# nrf54h20_enga_application register map
Vendor: Nordic Semiconductor; Series: nRF54h; File version: 1
CPU: CM33 r0p4, little endian, MPU, FPU, 3 interrupt priority bits, 480 interrupts, 4 SAU regions
Registers are 32-bit, read-write, reset 0x0 unless marked. A register's access mark holds for its fields unless they carry their own. Offsets are from the block's base; [hi:lo] are bit positions; lines under a group give offsets from that group; {n}, {i} and the like mark numbered series; 'fields as' and 'values as' point back to an identical list.

## GLOBAL_EXMIF_NS — External Memory Interface 0
Base 0x4F095000
Same registers: GLOBAL_EXMIF_S 0x5F095000
0x00 TASKS_START wo — Start operation.
  [0] TASKS_START
    1=Trigger task
0x04 TASKS_STOP wo — Stop operation.
  [0] TASKS_STOP
    1=Trigger task
0x100 EVENTS_CORE — Event indicating that interrupt triggered at EXMIF core
  [0] EVENTS_CORE
    0=NotGenerated (Event not generated); 1=Generated (Event generated)
0x300 INTEN — Enable or disable interrupt
  [0] CORE — Enable or disable interrupt for event CORE
    0=Disabled; 1=Enabled
0x304 INTENSET — Enable interrupt
  [0] CORE — Write '1' to enable interrupt for event CORE
    on read: 0=Disabled (Read: Disabled); 1=Enabled (Read: Enabled) | on write: 1=Set (Enable)
0x308 INTENCLR — Disable interrupt
  [0] CORE — Write '1' to disable interrupt for event CORE
    on read: 0=Disabled (Read: Disabled); 1=Enabled (Read: Enabled) | on write: 1=Clear (Disable)
0x30C INTPEND ro — Pending interrupts
  [0] CORE — Read pending status of interrupt for event CORE
    on read: 0=NotPending (Read: Not pending); 1=Pending (Read: Pending)
0x400 STRUCT0 group — Deprecated registergroup -
  0x00 ADDRESS1LO — Address offset for external memory device 1.
    [31:0] OFFSET — External memory Offset.
  0x04 ADDRESS1HI reset 0xFFFFFFF — Upper address range for external memory device 1.
    [31:0] ADDRESS — Upper limit address.
  0x08 ADDRESS2LO reset 0x10000000 — Address offset for external memory device 2.
    [31:0] OFFSET — External memory Offset.
  0x0C ADDRESS2HI reset 0x1FFFFFFF — Upper address range for external memory device 2.
    [31:0] ADDRESS — Upper limit address.
  0x10 EXTMEMEN — Enable or disable external memory access.
    [0] ENABLE — Enable or disable external memory access from AXI interface.
      0=Disabled (Disable external memory.); 1=Enabled (Enable external memory.)
  0x20 EXTMEM2 reset 0x1 — Enable external memory 2.
    [0] ENABLE
      0=Disabled (Disable external memory 2.); 1=Enabled (Enable external memory 2.)
0x400 EXTCONF1 group (alternate view of STRUCT0) — Configuration for external memory device 1.
  0x00 OFFSET — Address offset for external memory device 1.
    [31:0] OFFSET — External memory Offset.
  0x04 SIZE reset 0xFFFFFFF — Upper address range for external memory device 1.
    [31:0] SIZE — Upper limit address.
  0x10 ENABLE — Enable or disable external memory access.
    fields as STRUCT0.EXTMEMEN
0x400 EXTCONF2 group (alternate view of STRUCT0) — Configuration for external memory device 2.
  0x08 OFFSET — Address offset for external memory device 2.
    [31:0] OFFSET — External memory Offset.
  0x0C SIZE reset 0xFFFFFFF — Upper address range for external memory device 2.
    [31:0] SIZE — Upper limit address.
  0x20 ENABLE — Enable or disable external memory access.
    fields as STRUCT0.EXTMEMEN
0x400 STRUCT1 group (alternate view of STRUCT0) — Unspecified
  0x14 LOCKEDACCESS — Enable or disable locked APB access to serial memory controller.
    [0] ENABLE — Enable or disable locked APB access to SSI.
      0=Disabled (Disable locked APB access.); 1=Enabled (Enable locked APB access.)
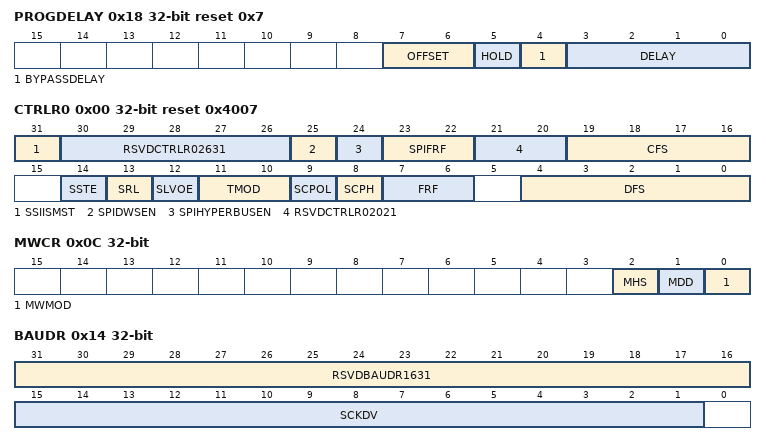
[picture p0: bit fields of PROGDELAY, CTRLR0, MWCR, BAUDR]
  0x18 PROGDELAY reset 0x7 — Configures delay of the incoming data strobe.
    [7:6] OFFSET — Delay offset for automatic delay calculation
      0=NoOffset; 1=OffsetPos1 (Offset is +1.); 2=OffsetNeg1 (Offset is -1.)
    [5] HOLD — Hold the delay value
      0=Disabled (Outgoing delay setting is updated.); 1=Enabled (Outgoing delay setting is not updated.)
    [4] BYPASSDELAY — Bypass delay calculated internally
      0=NotBypassed (Delay value calculated internally.); 1=Bypassed (Delay value used from the PROGDELAY register.)
    [3:0] DELAY — Delay value.
      0=NoDelay; 1=1 delay element; {v}={v} delay elements (v=2..12)
  0x1C RESET — Reset the external memory.
    [0] RESET
      0=Clear (Reset is cleared.); 1=Set (Reset is set.)
0x500 CORE group — Unspecified
  0x00 SSICADDRESS group — Unspecified
    0x00 CTRLR0 reset 0x4007 — This register controls the serial data transfer.
      [31] SSIISMST ro — This field selects if DWC_ssi is working in Master or Slave mode
        0=SLAVE (Unspecified); 1=MASTER (Unspecified)
      [30:26] RSVDCTRLR02631 ro — Reserved bits - read as zero
      [25] SPIDWSEN ro — Enable Dynamic wait states in SPI mode of operation.
        0=DISABLE (Unspecified); 1=ENABLE (Unspecified)
      [24] SPIHYPERBUSEN — SPI Hyperbus Frame format enable.
        0=DISABLE (Unspecified); 1=ENABLE (Unspecified)
      [23:22] SPIFRF — SPI Frame Format
        0=SPI_STANDARD (Unspecified); 1=SPI_DUAL (Unspecified); 2=SPI_QUAD (Unspecified); 3=SPI_OCTAL (Unspecified)
      [21:20] RSVDCTRLR02021 ro — Reserved bits - read as zero
      [19:16] CFS — Control Frame Size.
        {v}=SIZE_{v+1:02}_BIT (Unspecified) (v=0..15)
      [14] SSTE — Slave Select Toggle Enable.
        0=TOGGLE_DISABLE (Unspecified); 1=TOGGLE_EN (Unspecified)
      [13] SRL — Shift Register Loop.
        0=NORMAL_MODE (Unspecified); 1=TESTING_MODE (Unspecified)
      [12] SLVOE — Slave Output Enable.
        0=ENABLED (Unspecified); 1=DISABLED (Unspecified)
      [11:10] TMOD — Transfer Mode.
        0=TX_AND_RX (Unspecified); 1=TX_ONLY (Unspecified); 2=RX_ONLY (Unspecified); 3=EEPROM_READ (Unspecified)
      [9] SCPOL — Serial Clock Polarity.
        0=INACTIVE_HIGH (Unspecified); 1=INACTIVE_LOW (Unspecified)
      [8] SCPH — Serial Clock Phase.
        0=MIDDLE_BIT (Unspecified); 1=START_BIT (Unspecified)
      [7:6] FRF — Frame Format.
        0=SPI (Unspecified); 1=SSP (Unspecified); 2=MICROWIRE (Unspecified)
      [4:0] DFS — Data Frame Size.
        {v}=DFS_{v+1:02}_BIT (Unspecified) (v=0..31)
    0x04 CTRLR1 — This register exists only when the DWC_ssi is configured as a master device.
      [15:0] NDF — Number of Data Frames.
    0x08 SSIENR — This register enables and disables the DWC_ssi.
      [0] SSICEN — SSI Enable.
        0=DISABLE (Unspecified); 1=ENABLED (Unspecified)
    0x0C MWCR — This register controls the direction of the data word for the half-duplex Microwire serial protocol.
      [2] MHS — Microwire Handshaking.
        0=DISABLE (Unspecified); 1=ENABLED (Unspecified)
      [1] MDD — Microwire Control.
        0=RECEIVE (Unspecified); 1=TRANSMIT (Unspecified)
      [0] MWMOD — Microwire Transfer Mode.
        0=NON_SEQUENTIAL (Unspecified); 1=SEQUENTIAL (Unspecified)
    0x10 SER — This register is valid only when the DWC_ssi is configured as a master device.
      [1:0] SER — Slave Select Enable Flag.
        0=NOTSELECTED (Unspecified); 1=SELECTED (Unspecified)
    0x14 BAUDR — This register is valid only when the DWC_ssi is configured as a master device.
      [31:16] RSVDBAUDR1631 ro — Reserved bits - read as zero
      [15:1] SCKDV — SSI Clock Divider.
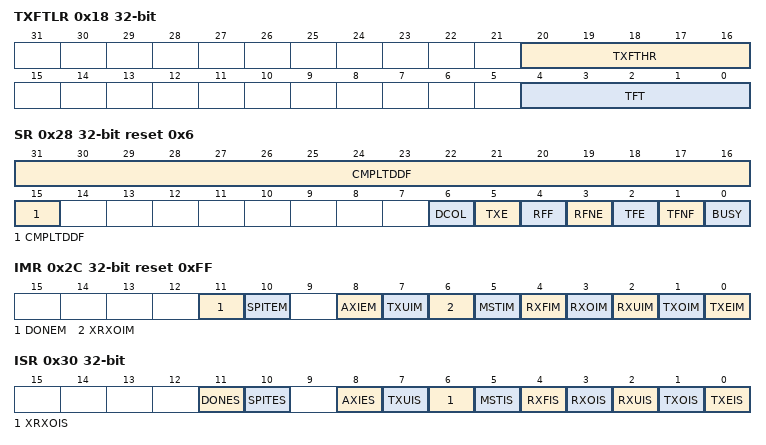
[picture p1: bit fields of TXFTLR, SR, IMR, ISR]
    0x18 TXFTLR — This register controls the threshold value for the transmit FIFO memory..
      [20:16] TXFTHR — Transfer start FIFO level.
      [4:0] TFT — Transmit FIFO Threshold.
    0x1C RXFTLR — This register controls the threshold value for the receive FIFO memory..
      [4:0] RFT — Receive FIFO Threshold.
    0x20 TXFLR — This register contains the number of valid data entries in the transmit FIFO memory.
      [5:0] TXTFL ro — Transmit FIFO Level.
    0x24 RXFLR — This register contains the number of valid data entries in the receive FIFO memory.
      [5:0] RXTFL ro — Receive FIFO Level.
    0x28 SR reset 0x6 — This is a read-only register used to indicate the current transfer status, FIFO status, and any transmission/reception errors that may have occurred.
      [31:15] CMPLTDDF ro — Completed Data frames
      [6] DCOL ro — Data Collision Error.
        0=NO_ERROR_CONDITION (Unspecified); 1=TX_COLLISION_ERROR (Unspecified)
      [5] TXE ro — Transmission Error.
        0=NO_ERROR (Unspecified); 1=TX_ERROR (Unspecified)
      [4] RFF ro — Receive FIFO Full.
        0=NOT_FULL (Unspecified); 1=FULL (Unspecified)
      [3] RFNE ro — Receive FIFO Not Empty.
        0=EMPTY (Unspecified); 1=NOT_EMPTY (Unspecified)
      [2] TFE ro — Transmit FIFO Empty.
        0=NOT_EMPTY (Unspecified); 1=EMPTY (Unspecified)
      [1] TFNF ro — Transmit FIFO Not Full.
        0=FULL (Unspecified); 1=NOT_FULL (Unspecified)
      [0] BUSY ro — SSI Busy Flag.
        0=INACTIVE (Unspecified); 1=ACTIVE (Unspecified)
    0x2C IMR reset 0xFF — This read/write register masks or enables all interrupts generated by the DWC_ssi.
      [11] DONEM ro — SSI Done Interrupt Mask
        0=MASKED (Unspecified); 1=UNMASKED (Unspecified)
      [10] SPITEM ro — SPI Transmit Error Interrupt Mask
        0=MASKED (Unspecified); 1=UNMASKED (Unspecified)
      [8] AXIEM ro — AXI Error Interrupt Mask
        0=MASKED (Unspecified); 1=UNMASKED (Unspecified)
      [7] TXUIM — Transmit FIFO Underflow Interrupt Mask
        0=MASKED (Unspecified); 1=UNMASKED (Unspecified)
      [6] XRXOIM — XIP Receive FIFO Overflow Interrupt Mask
        0=MASKED (Unspecified); 1=UNMASKED (Unspecified)
      [5] MSTIM — Multi-Master Contention Interrupt Mask.
        0=MASKED (Unspecified); 1=UNMASKED (Unspecified)
      [4] RXFIM — Receive FIFO Full Interrupt Mask
        0=MASKED (ssi_rxf_intr interrupt is masked); 1=UNMASKED (ssi_rxf_intr interrupt is not masked)
      [3] RXOIM — Receive FIFO Overflow Interrupt Mask
        0=MASKED (Unspecified); 1=UNMASKED (Unspecified)
      [2] RXUIM — Receive FIFO Underflow Interrupt Mask
        0=MASKED (Unspecified); 1=UNMASKED (Unspecified)
      [1] TXOIM — Transmit FIFO Overflow Interrupt Mask
        0=MASKED (Unspecified); 1=UNMASKED (Unspecified)
      [0] TXEIM — Transmit FIFO Empty Interrupt Mask
        0=MASKED (Unspecified); 1=UNMASKED (Unspecified)
    0x30 ISR — This register reports the status of the DWC_ssi interrupts after they have been masked.
      [all] fields
        0=INACTIVE (Unspecified); 1=ACTIVE (Unspecified)
      [11] DONES ro — SSI Done Interrupt Status
      [10] SPITES ro — SPI Transmit Error Interrupt
      [8] AXIES ro — AXI Error Interrupt Status
      [7] TXUIS ro — Transmit FIFO Underflow Interrupt Status
      [6] XRXOIS ro — XIP Receive FIFO Overflow Interrupt Status
      [5] MSTIS ro — Multi-Master Contention Interrupt Status.
      [4] RXFIS ro — Receive FIFO Full Interrupt Status
      [3] RXOIS ro — Receive FIFO Overflow Interrupt Status
      [2] RXUIS ro — Receive FIFO Underflow Interrupt Status
      [1] TXOIS ro — Transmit FIFO Overflow Interrupt Status
      [0] TXEIS ro — Transmit FIFO Empty Interrupt Status
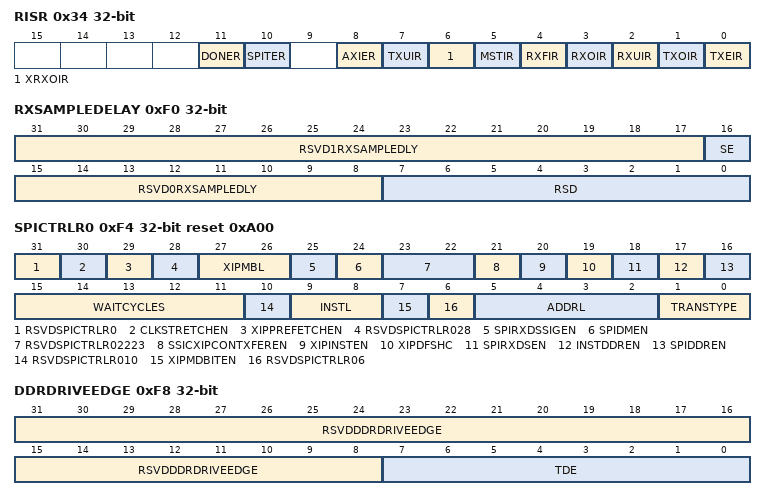
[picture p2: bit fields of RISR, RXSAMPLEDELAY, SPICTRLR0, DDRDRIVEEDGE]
    0x34 RISR — Raw Interrupt Status Register
      [all] fields
        0=INACTIVE (Unspecified); 1=ACTIVE (Unspecified)
      [11] DONER ro — SSI Done Interrupt Raw Status
      [10] SPITER ro — SPI Transmit Error Interrupt status.
      [8] AXIER ro — AXI Error Interrupt Raw Status
      [7] TXUIR ro — Transmit FIFO Underflow Interrupt Raw Status
      [6] XRXOIR ro — XIP Receive FIFO Overflow Raw Interrupt Status
      [5] MSTIR ro — Multi-Master Contention Raw Interrupt Status.
      [4] RXFIR ro — Receive FIFO Full Raw Interrupt Status
      [3] RXOIR ro — Receive FIFO Overflow Raw Interrupt Status
      [2] RXUIR ro — Receive FIFO Underflow Raw Interrupt Status
      [1] TXOIR ro — Transmit FIFO Overflow Raw Interrupt Status
      [0] TXEIR ro — Transmit FIFO Empty Raw Interrupt Status
    0x38 TXEICR — Transmit FIFO Error Interrupt Clear Register
      [0] TXEICR ro — Clear Transmit FIFO Overflow/Underflow Interrupt.
    0x3C RXOICR — Receive FIFO Overflow Interrupt Clear Register
      [0] RXOICR ro — Clear Receive FIFO Overflow Interrupt.
    0x40 RXUICR — Receive FIFO Underflow Interrupt Clear Register
      [0] RXUICR ro — Clear Receive FIFO Underflow Interrupt.
    0x44 MSTICR — Multi-Master Interrupt Clear Register
      [0] MSTICR ro — Clear Multi-Master Contention Interrupt.
    0x48 ICR — Interrupt Clear Register
      [0] ICR ro — Clear Interrupts.
    0x58 IDR reset 0x10003 — This register contains the peripherals identification code, which is written into the register at configuration time using coreConsultant.
      [31:0] IDCODE ro — Identification code.
    0x5C SSICVERSIONID reset 0x3130332A — This read-only register stores the specific DWC_ssi component version.
      [31:0] SSICCOMPVERSION ro — Contains the hex representation of the Synopsys component version.
    {0x60+4k} DR[{k}] (k=0..35) — Description collection: The DWC_ssi data register is a 32-bit read/write buffer for the transmit/receive FIFOs.
      [31:0] DR — Data Register.
    0xF0 RXSAMPLEDELAY — This register is only valid when the DWC_ssi is configured with rxd sample delay logic (SSIC_HAS_RX_SAMPLE_DELAY==1).
      [31:17] RSVD1RXSAMPLEDLY ro — Reserved bits - read as zero
      [16] SE — Receive Data (rxd) Sampling Edge.
      [15:8] RSVD0RXSAMPLEDLY ro — Reserved bits - read as zero
      [7:0] RSD — Receive Data (rxd) Sample Delay.
    0xF4 SPICTRLR0 reset 0xA00 — This register is used to control the serial data transfer in enhanced SPI mode of operation.
      [31] RSVDSPICTRLR0 ro — Reserved bits - read as zero
      [30] CLKSTRETCHEN — Enables clock stretching capability in SPI transfers.
      [29] XIPPREFETCHEN ro — Enables XIP pre-fetch functionality in DWC_ssi.
      [28] RSVDSPICTRLR028 ro — Reserved bits - read as zero
      [27:26] XIPMBL ro — XIP Mode bits length.
        0=MBL_2 (Unspecified); 1=MBL_4 (Unspecified); 2=MBL_8 (Unspecified); 3=MBL_16 (Unspecified)
      [25] SPIRXDSSIGEN — Enable rxds signaling during address and command phase of Hyperbus transfer.
      [24] SPIDMEN — SPI data mask enable bit.
      [23:22] RSVDSPICTRLR02223 ro — Reserved bits - read as zero
      [21] SSICXIPCONTXFEREN ro — Enable continuous transfer in XIP mode.
      [20] XIPINSTEN ro — XIP instruction enable bit.
      [19] XIPDFSHC ro — Fix DFS for XIP transfers.
      [18] SPIRXDSEN — Read data strobe enable bit.
      [17] INSTDDREN — Instruction DDR Enable bit.
      [16] SPIDDREN — SPI DDR Enable bit.
      [15:11] WAITCYCLES — Wait cycles in Dual/Quad/Octal mode between control frames transmit and data reception.
      [10] RSVDSPICTRLR010 ro — Reserved bits - read as zero
      [9:8] INSTL — Dual/Quad/Octal mode instruction length in bits.
        0=INST_L0 (Unspecified); 1=INST_L4 (Unspecified); 2=INST_L8 (Unspecified); 3=INST_L16 (Unspecified)
      [7] XIPMDBITEN ro — Mode bits enable in XIP mode.
      [6] RSVDSPICTRLR06 ro — Reserved bits - read as zero
      [5:2] ADDRL — This bit defines Length of Address to be transmitted.
        0=ADDR_L0 (Unspecified); 1=ADDR_L4 (Unspecified); 2=ADDR_L8 (Unspecified); 3=ADDR_L12 (Unspecified); 4=ADDR_L16 (Unspecified); 5=ADDR_L20 (Unspecified); 6=ADDR_L24 (Unspecified); 7=ADDR_L28 (Unspecified); 8=ADDR_L32 (Unspecified); 9=ADDR_L36 (Unspecified); 10=ADDR_L40 (Unspecified); 11=ADDR_L44 (Unspecified); 12=ADDR_L48 (Unspecified); 13=ADDR_L52 (Unspecified); 14=ADDR_L56 (Unspecified); 15=ADDR_L60 (Unspecified)
      [1:0] TRANSTYPE — Address and instruction transfer format.
        {v}=TT{v} (Unspecified) (v=0..3)
    0xF8 DDRDRIVEEDGE — This Register is valid only when SSIC_HAS_DDR is equal to 1.
      [31:8] RSVDDDRDRIVEEDGE ro — Reserved bits - read as zero
      [7:0] TDE — TXD Drive edge register which decided the driving edge of transmit data.
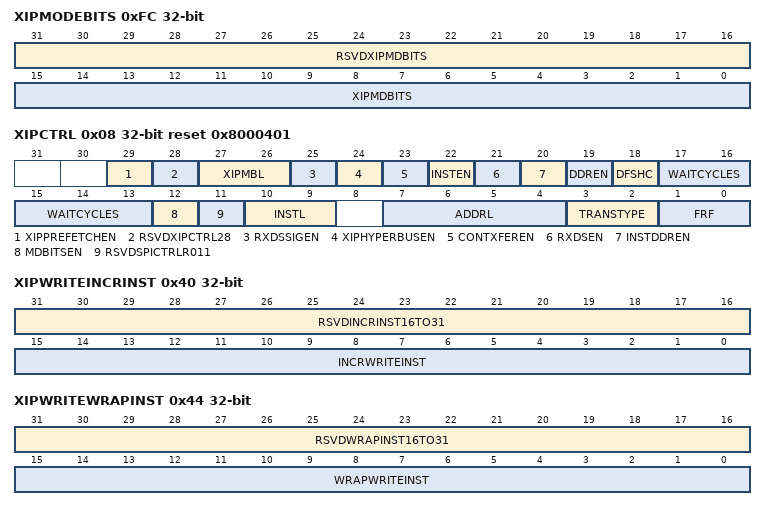
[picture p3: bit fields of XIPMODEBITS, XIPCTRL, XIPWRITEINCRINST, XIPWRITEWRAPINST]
    0xFC XIPMODEBITS — This register carries the mode bits which are sent in the XIP mode of operation after address phase.
      [31:16] RSVDXIPMDBITS ro — Reserved bits - read as zero
      [15:0] XIPMDBITS — XIP mode bits to be sent after address phase of XIP transfer.
  0x100 SSICXIPADDRESS group — Unspecified
    0x00 XIPINCRINST — This Register is valid only when SSIC_XIP_EN is equal to 1.
      [15:0] INCRINST — XIP INCR transfer opcode.
    0x04 XIPWRAPINST — This Register is valid only when SSIC_XIP_EN is equal to 1.
      [15:0] WRAPINST — XIP WRAP transfer opcode.
    0x08 XIPCTRL reset 0x8000401 — This Register is valid only when SSIC_CONCURRENT_XIP_EN is equal to 1.
      [29] XIPPREFETCHEN — Enables XIP pre-fetch functionality in DWC_ssi.
      [28] RSVDXIPCTRL28 ro — Reserved bits - read as zero
      [27:26] XIPMBL — XIP Mode bits length.
        values as CORE.SSICADDRESS.SPICTRLR0.XIPMBL
      [25] RXDSSIGEN — Enable rxds signaling during address and command phase of Hyperbus transfer.
      [24] XIPHYPERBUSEN — SPI Hyperbus Frame format enable for XIP transfers.
      [23] CONTXFEREN ro — Enable continuous transfer in XIP mode.
      [22] INSTEN — XIP instruction enable bit.
      [21] RXDSEN — Read data strobe enable bit.
      [20] INSTDDREN — Instruction DDR Enable bit.
      [19] DDREN — SPI DDR Enable bit.
      [18] DFSHC — Fix DFS for XIP transfers.
      [17:13] WAITCYCLES — Wait cycles in Dual/Quad/Octal mode between control frames transmit and data reception.
      [12] MDBITSEN — Mode bits enable in XIP mode.
      [11] RSVDSPICTRLR011 ro — Reserved bits - read as zero
      [10:9] INSTL — Dual/Quad/Octal mode instruction length in bits.
        values as CORE.SSICADDRESS.SPICTRLR0.INSTL
      [7:4] ADDRL — This bit defines Length of Address to be transmitted.
        values as CORE.SSICADDRESS.SPICTRLR0.ADDRL
      [3:2] TRANSTYPE — Address and instruction transfer format.
        {v}=TT{v} (Unspecified) (v=0..3)
      [1:0] FRF — SPI Frame Format
        0=RSVD (Unspecified); 1=SPI_DUAL (Unspecified); 2=SPI_QUAD (Unspecified); 3=SPI_OCTAL (Unspecified)
    0x10 XRXOICR — XIP Receive FIFO Overflow Interrupt Clear Register
      [0] XRXOICR ro — Clear XIP Receive FIFO Overflow Interrupt.
    0x40 XIPWRITEINCRINST — This Register is valid only when both SSIC_XIP_WRITE_REG_EN is set to 1.
      [31:16] RSVDINCRINST16TO31 ro — Reserved bits - Read Only
      [15:0] INCRWRITEINST — XIP Write INCR transfer opcode.
    0x44 XIPWRITEWRAPINST — This Register is valid only when both SSIC_XIP_WRITE_REG_EN is set to 1.
      [31:16] RSVDWRAPINST16TO31 ro — Reserved bits - Read Only
      [15:0] WRAPWRITEINST — XIP Write WRAP transfer opcode.
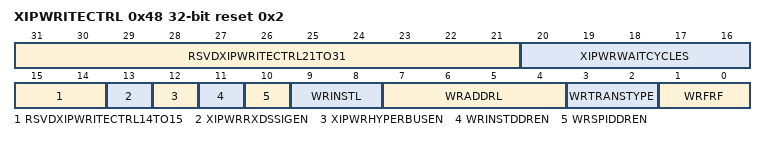
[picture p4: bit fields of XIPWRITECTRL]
    0x48 XIPWRITECTRL reset 0x2 — This Register is valid only when SSIC_XIP_WRITE_REG_EN is equal to 1.
      [31:21] RSVDXIPWRITECTRL21TO31 ro — Reserved bits - Read Only
      [20:16] XIPWRWAITCYCLES — Wait cycles in Dual/Quad/Octal mode between control frames transmit and data reception.
      [15:14] RSVDXIPWRITECTRL14TO15 ro — Reserved bits - Read Only
      [13] XIPWRRXDSSIGEN — Enable rxds signaling during address and command phase of Hyperbus transfer.
      [12] XIPWRHYPERBUSEN — SPI Hyperbus Frame format enable for XIP Write transfers.
      [11] WRINSTDDREN — Instruction DDR Enable bit.
      [10] WRSPIDDREN — SPI DDR Enable bit.
      [9:8] WRINSTL — Dual/Quad/Octal mode instruction length in bits.
        values as CORE.SSICADDRESS.SPICTRLR0.INSTL
      [7:4] WRADDRL — This bit defines Length of Address to be transmitted.
        0=ADDR_L0 (Unspecified); 1=ADDR_L4 (Unspecified); 2=ADDR_L8 (Unspecified); 3=ADDR_L12 (Unspecified); 4=ADDR_L16 (Unspecified); 5=ADDR_L20 (Unspecified); 6=ADDR_L24 (Unspecified); 7=ADDR_L28 (Unspecified); 8=ADDR_L32 (Unspecified)
      [3:2] WRTRANSTYPE — Address and instruction transfer format.
        {v}=TT{v} (Unspecified) (v=0..3)
      [1:0] WRFRF — SPI Frame Format
        values as CORE.SSICXIPADDRESS.XIPCTRL.FRF
